# STM32H73x register map
File version: 1.0
CPU: CM7 r0p1, little endian, MPU, FPU, 4 interrupt priority bits
Registers are 32-bit, read-write, reset 0x0 unless marked. A register's access mark holds for its fields unless they carry their own. Offsets are from the block's base; [hi:lo] are bit positions; {n}, {i} and the like mark numbered series.

## RAMECC2 — ECC controller is associated to each RAM area
Base 0x48023000
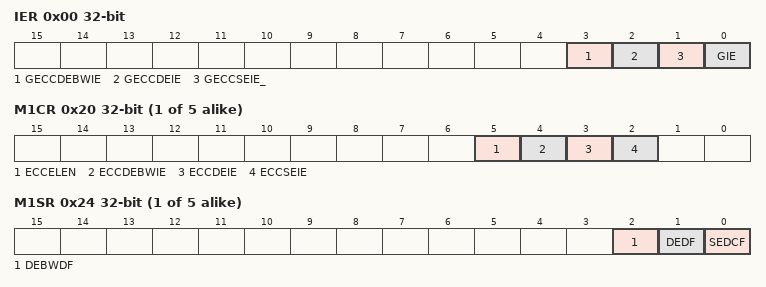
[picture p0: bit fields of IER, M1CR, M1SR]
0x00 IER — RAMECC interrupt enable register
  [3] GECCDEBWIE — Global ECC double error on byte write (BW) interrupt enable
  [2] GECCDEIE — Global ECC double error interrupt enable
  [1] GECCSEIE_ — Global ECC single error interrupt enable
  [0] GIE — Global interrupt enable
{0x0+0x20*i} M{i}CR (i=1..5) — RAMECC monitor x configuration register
  [5] ECCELEN — ECC error latching enable
  [4] ECCDEBWIE — ECC double error on byte write (BW) interrupt enable
  [3] ECCDEIE — ECC double error interrupt enable
  [2] ECCSEIE — ECC single error interrupt enable
{0x4+0x20*i} M{i}SR (i=1..5) — RAMECC monitor x status register
  [2] DEBWDF — ECC double error on byte write (BW) detected flag
  [1] DEDF — ECC double error detected flag
  [0] SEDCF — ECC single error detected and corrected flag
{0x8+0x20*i} M{i}FAR ro (i=1..4) — RAMECC monitor x failing address register
  [31:0] FADD — ECC error failing address
{0xC+0x20*i} M{i}FDRL ro (i=1..5) — RAMECC monitor x failing data low register
  [31:0] FDATAL — Failing data low
0x30 M1FDRH ro — RAMECC monitor x failing data high register
  [31:0] FDATAH — Failing data high (64-bit memory)
0x34 M1FECR — RAMECC monitor x failing ECC error code register
  [31:0] FEC — Failing error code
0x50 M2FDRH — RAMECC monitor x failing data high register
  [31:0] FDATAH — Failing data high (64-bit memory)
0x58 M2FECR — RAMECC monitor x failing ECC error code register
  [31:0] FEC — Failing error code
0x70 M3FDRH ro — RAMECC monitor x failing data high register
  [31:0] FDATAH — Failing data high (64-bit memory)
0x7C M3FECR ro — RAMECC monitor x failing ECC error code register
  [31:0] FEC — Failing error code
0x90 M4FDRH ro — RAMECC monitor x failing data high register
  [31:0] FDATAH — Failing data high (64-bit memory)
0x90 M4FECR ro (alternate view of M4FDRH) — RAMECC monitor x failing ECC error code register
  [31:0] FEC — Failing error code
0xA8 M5FAR — RAMECC monitor x failing address register
  [31:0] FADD — ECC error failing address
0xB0 M5FDRH ro — RAMECC monitor x failing data high register
  [31:0] FEC — Failing error code
0xB4 M5FECR ro — RAMECC monitor x failing ECC error code register
  [31:0] FEC — Failing error code

## RAMECC3 — ECC controller is associated to each RAM area
Base 0x58027000
Registers as RAMECC2, without M{n}CR (n=3..5), M{n}SR (n=3..5), M{n}FAR (n=3..5), M{n}FDRL (n=3..5), M{n}FDRH (n=3..5), M{n}FECR (n=3..5).

## CRYP — Cryptographic processor
Base 0x48021000
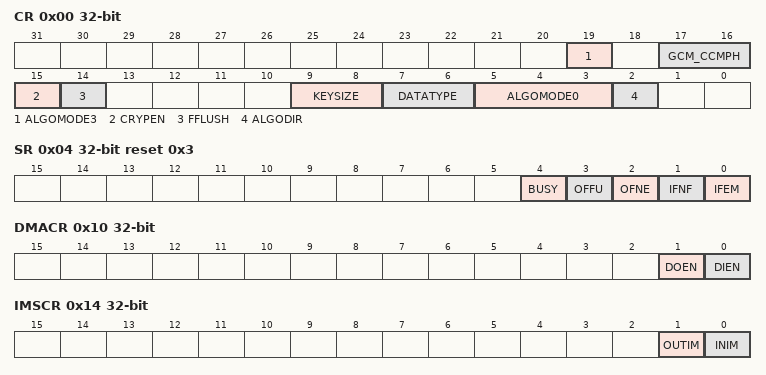
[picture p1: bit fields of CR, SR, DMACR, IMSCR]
0x00 CR access per field — control register
  [19] ALGOMODE3 rw — ALGOMODE
  [17:16] GCM_CCMPH rw
  [15] CRYPEN rw — Cryptographic processor enable
  [14] FFLUSH wo — FIFO flush
  [9:8] KEYSIZE rw — Key size selection (AES mode only)
  [7:6] DATATYPE rw — Data type selection
  [5:3] ALGOMODE0 rw — Algorithm mode
  [2] ALGODIR rw — Algorithm direction
0x04 SR ro reset 0x3 — status register
  [4] BUSY — Busy bit
  [3] OFFU — Output FIFO full
  [2] OFNE — Output FIFO not empty
  [1] IFNF — Input FIFO not full
  [0] IFEM — Input FIFO empty
0x08 DIN — data input register
  [31:0] DATAIN — Data input
0x0C DOUT ro — data output register
  [31:0] DATAOUT — Data output
0x10 DMACR — DMA control register
  [1] DOEN — DMA output enable
  [0] DIEN — DMA input enable
0x14 IMSCR — interrupt mask set/clear register
  [1] OUTIM — Output FIFO service interrupt mask
  [0] INIM — Input FIFO service interrupt mask
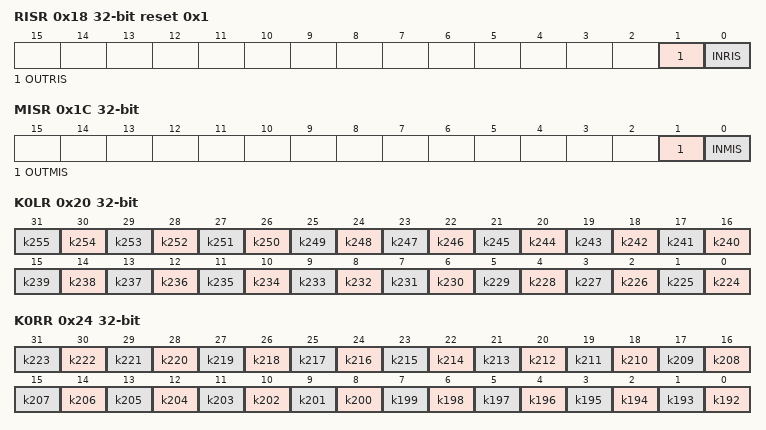
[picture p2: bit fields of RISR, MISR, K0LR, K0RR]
0x18 RISR ro reset 0x1 — raw interrupt status register
  [1] OUTRIS — Output FIFO service raw interrupt status
  [0] INRIS — Input FIFO service raw interrupt status
0x1C MISR ro — masked interrupt status register
  [1] OUTMIS — Output FIFO service masked interrupt status
  [0] INMIS — Input FIFO service masked interrupt status
0x20 K0LR wo — key registers
  [n-224] k{n} (n=224..255)
0x24 K0RR wo — key registers
  [n-192] k{n} (n=192..223)
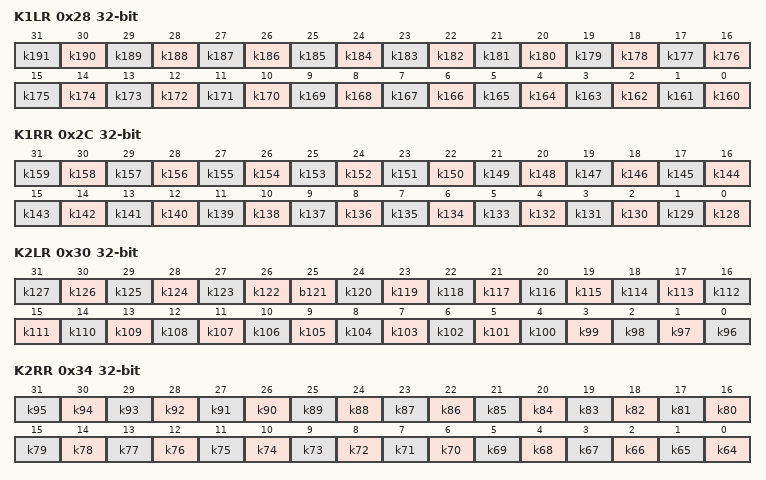
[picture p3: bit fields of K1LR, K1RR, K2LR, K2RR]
0x28 K1LR wo — key registers
  [n-160] k{n} (n=160..191)
0x2C K1RR wo — key registers
  [n-128] k{n} (n=128..159)
0x30 K2LR wo — key registers
  [n-96] k{n} (n=122..127), [25] b121, [n-96] k{n} (n=96..120)
0x34 K2RR wo — key registers
  [n-64] k{n} (n=64..95)
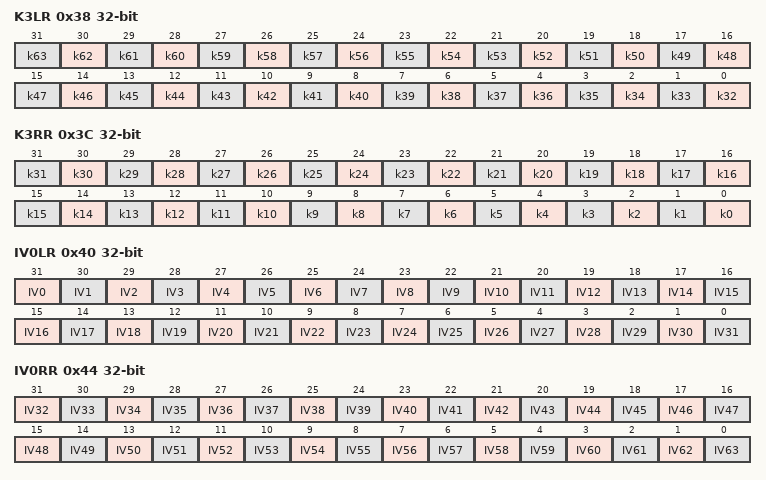
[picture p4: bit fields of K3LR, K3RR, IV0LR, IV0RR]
0x38 K3LR wo — key registers
  [n-32] k{n} (n=32..63)
0x3C K3RR wo — key registers
  [n] k{n} (n=0..31)
0x40 IV0LR — Initialization vector register 0L
  [31-n] IV{n} (n=0..31)
0x44 IV0RR — initialization vector register 0R
  [63-n] IV{n} (n=32..63)
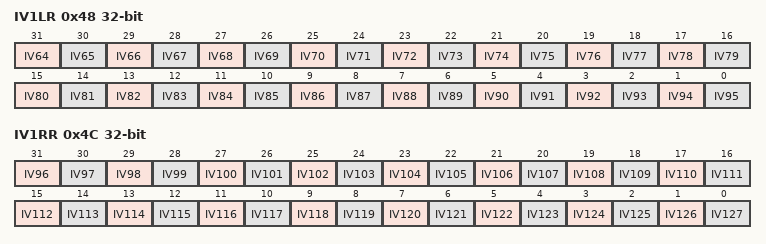
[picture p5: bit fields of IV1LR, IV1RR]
0x48 IV1LR — Initialization vector register 1L
  [95-n] IV{n} (n=64..95)
0x4C IV1RR — Initialization vector register 1R
  [127-n] IV{n} (n=96..127)
{0x50+4i} CSGCMCCM{i}R (i=0..7) — context swap register
{0x70+4i} CSGCM{i}R (i=0..7) — context swap register
